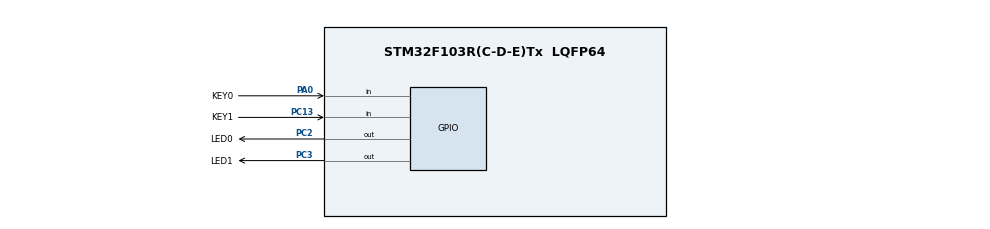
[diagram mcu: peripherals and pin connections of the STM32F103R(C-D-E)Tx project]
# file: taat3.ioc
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Mcu.Family=STM32F1
Mcu.Name=STM32F103R(C-D-E)Tx
Mcu.Package=LQFP64
NVIC.PriorityGroup=NVIC_PRIORITYGROUP_4
PA0-WKUP.GPIO_Label=KEY0
PA0-WKUP.Signal=GPIO_Input
PA13.Mode=Serial_Wire
PA13.Signal=SYS_JTMS-SWDIO
PA14.Mode=Serial_Wire
PA14.Signal=SYS_JTCK-SWCLK
PC13-TAMPER-RTC.GPIO_Label=KEY1
PC13-TAMPER-RTC.Signal=GPIO_Input
PC2.GPIO_Label=LED0
PC2.Signal=GPIO_Output
PC3.GPIO_Label=LED1
PC3.Signal=GPIO_Output
ProjectManager.HeapSize=0x200
ProjectManager.StackSize=0x400
ProjectManager.TargetToolchain=MDK-ARM V5.32
RCC.APB1Freq_Value=8000000
RCC.APB2Freq_Value=8000000
board=custom

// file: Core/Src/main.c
/* USER CODE BEGIN Header */
/**
  ******************************************************************************
  * @file           : main.c
  * @brief          : Main program body
  ******************************************************************************
  * @attention
  *
  * Copyright (c) 2026 STMicroelectronics.
  * All rights reserved.
  *
  * This software is licensed under terms that can be found in the LICENSE file
  * in the root directory of this software component.
  * If no LICENSE file comes with this software, it is provided AS-IS.
  *
  ******************************************************************************
  */
/* USER CODE END Header */
#include <stdint.h>
#include "main.h"
#include "gpio.h"

int led0_T(int add,int time)
{
	return add+time;
}

void SystemClock_Config(void);

int main(void)
{

	uint16_t led0_start_time = 0;
<<<<<<< HEAD
	uint16_t led0_add = 250;
=======
	uint16_t led0_add = 500;
>>>>>>> 549c90100fe6ee3058708b41819c73bc52cf9fa8

	uint8_t key0_read_last = 1;
	uint32_t last_key0_tick = 0;//时刻

  /* MCU Configuration--------------------------------------------------------*/

  /* Reset of all peripherals, Initializes the Flash interface and the Systick. */
  HAL_Init();

  /* Configure the system clock */
  SystemClock_Config();

  /* Initialize all configured peripherals */
  MX_GPIO_Init();
  /* USER CODE BEGIN 2 */
	HAL_GPIO_WritePin(GPIOC,GPIO_PIN_3,GPIO_PIN_SET);
  /* USER CODE END 2 */

  /* Infinite loop */
  /* USER CODE BEGIN WHILE */
  while (1)
  {

		uint32_t cur=HAL_GetTick();
		if(cur - led0_start_time >= led0_add)
		{
			led0_start_time = cur;
			HAL_GPIO_TogglePin(LED0_GPIO_Port,LED0_Pin);
		}

		uint8_t key0_read_now = HAL_GPIO_ReadPin(KEY0_GPIO_Port,KEY0_Pin);

		if((key0_read_now == 0)&&(key0_read_last == 1)&&(led0_add<=2000))
		{
			if((key0_read_now == 0)&&(cur - last_key0_tick >=20))
			{
				led0_add +=250;
				last_key0_tick = cur;
			}
		}
    /* USER CODE END WHILE */
		key0_read_last = key0_read_now;//将现在的电平状态替换成下一次要用的
  }
}

void SystemClock_Config(void)
{
  RCC_OscInitTypeDef RCC_OscInitStruct = {0};
  RCC_ClkInitTypeDef RCC_ClkInitStruct = {0};

  /** Initializes the RCC Oscillators according to the specified parameters
  * in the RCC_OscInitTypeDef structure.
  */
  RCC_OscInitStruct.OscillatorType = RCC_OSCILLATORTYPE_HSI;
  RCC_OscInitStruct.HSIState = RCC_HSI_ON;
  RCC_OscInitStruct.HSICalibrationValue = RCC_HSICALIBRATION_DEFAULT;
  RCC_OscInitStruct.PLL.PLLState = RCC_PLL_NONE;
  if (HAL_RCC_OscConfig(&RCC_OscInitStruct) != HAL_OK)
  {
    Error_Handler();
  }

  /** Initializes the CPU, AHB and APB buses clocks
  */
  RCC_ClkInitStruct.ClockType = RCC_CLOCKTYPE_HCLK|RCC_CLOCKTYPE_SYSCLK
                              |RCC_CLOCKTYPE_PCLK1|RCC_CLOCKTYPE_PCLK2;
  RCC_ClkInitStruct.SYSCLKSource = RCC_SYSCLKSOURCE_HSI;
  RCC_ClkInitStruct.AHBCLKDivider = RCC_SYSCLK_DIV1;
  RCC_ClkInitStruct.APB1CLKDivider = RCC_HCLK_DIV1;
  RCC_ClkInitStruct.APB2CLKDivider = RCC_HCLK_DIV1;

  if (HAL_RCC_ClockConfig(&RCC_ClkInitStruct, FLASH_LATENCY_0) != HAL_OK)
  {
    Error_Handler();
  }
}

void Error_Handler(void)
{
  __disable_irq();
  while (1)
  {
  }
}
